AUTOSAR XML (schema 00052)
package /apd/AdaptiveApplicationSwComponentTypes
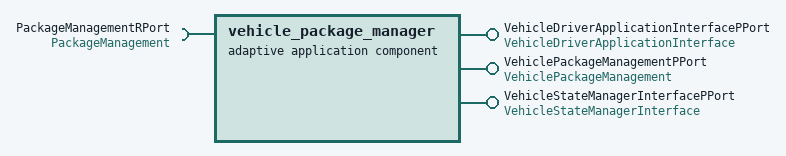
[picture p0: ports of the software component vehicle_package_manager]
  adaptive application sw component type vehicle_package_manager
    require port PackageManagementRPort: required-interface=PackageManagement
    provide port VehicleDriverApplicationInterfacePPort: provided-interface=VehicleDriverApplicationInterface
    provide port VehiclePackageManagementPPort: provided-interface=VehiclePackageManagement
    provide/require port VehiclePackageTransferStatusPRPort: provided-required-interface=VehiclePackageTransferStatus
    provide port VehicleStateManagerInterfacePPort: provided-interface=VehicleStateManagerInterface
package /apd/Executables
  executable vehicle_package_manager: category=PLATFORM_LEVEL, build-type=BUILD-TYPE-DEBUG, minimum-timer-granularity=1000.0, version=1.0.0
    root sw component prototype vehicle_package_manager_root: application-type=vehicle_package_manager
